# SYNTH32 register map
Vendor: SYNTH-Corp; File version: 1.0
Synthetic device for embedded-toolkit tests
CPU: CM4 r0p1, little endian
Registers are access not given, reset 0x0 unless marked. A register's access mark holds for its fields unless they carry their own. Offsets are from the block's base; lines under a group give offsets from that group; [hi:lo] are bit positions; {n}, {i} and the like mark numbered series; 'fields as' and 'values as' point back to an identical list; <NAME> marks a mode.

## Memory map
0x40004400 USART2 size 0x400
0x40004800 USART3 size 0x400
0x40010400 EXTI — External interrupt/event controller
0x40012C00 TIM1
0x40013800 USART1 size 0x400 — Synthetic USART 1
0x40020000 DMA1
0x40021000 RCC
0x48000000 GPIO{x} (x=A,B,C; step 0x400) — Synthetic GPIO port
0xE000E100 NVIC — 嵌套向量中断控制器（Synthetic）

## Interrupts
11 DMA1_Channel1_IRQn (DMA1) — DMA1 channel 1 interrupt
12 DMA1_Channel2_IRQn (DMA1)
37 USART1_IRQn (USART1) — USART1 global interrupt
39 USART3_IRQn (USART3)

## USART1 — Synthetic USART 1
Base 0x40013800
Same registers: USART2 0x40004400
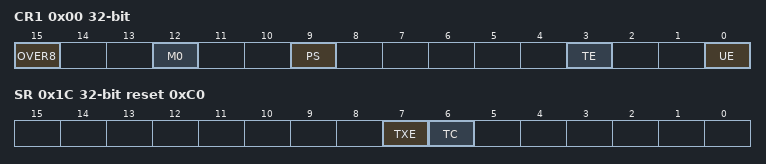
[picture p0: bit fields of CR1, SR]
0x00 CR1 32-bit rw — Control register 1
  [15] OVER8 — Oversampling mode
  [12] M0 — Word length
  [9] PS — Parity selection
    0=EVEN (Even parity); 1=ODD (Odd parity); other=DEFAULT
  [3] TE — Transmitter enable
  [0] UE — USART enable
0x0C BRR — Baud rate register
  [15:0] DIV — Baud rate divisor
0x1C SR ro reset 0xC0 — Status register
  [7] TXE — Transmit data register empty
  [6] TC rw — Transmission complete

## USART3
Base 0x40004800
Registers as USART1; these are added or differ:
0x1C SR reset 0x40
  [7] TXE

## GPIO{x} — Synthetic GPIO port
Base 0x48000000; array of 3, step 0x400
0x00 MODER 32-bit reset 0x1
  [1:0] MODE0 — Port mode bit 0
    0=INPUT; 1=OUTPUT; 2=ALTERNATE; 3=ANALOG
0x14 ODR 16-bit
  [0] OD0

## DMA1
Base 0x40020000
0x00 ISR
  [0] GIF1
0x08 CH{i} (i=1..2; step 0x14) group — DMA channel
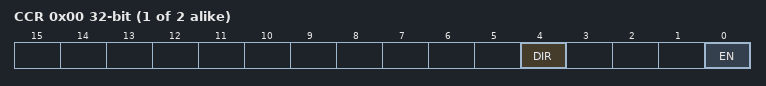
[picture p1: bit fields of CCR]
  0x00 CCR
    [4] DIR, [0] EN
  0x04 CNDTR
    [15:0] NDT

## TIM1
Base 0x40012C00
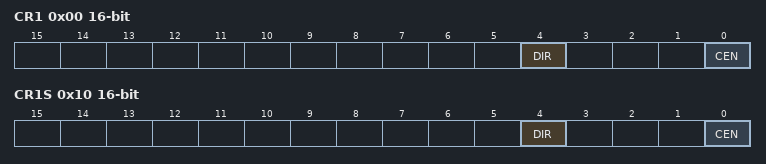
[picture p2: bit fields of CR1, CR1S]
0x00 CR1 16-bit — TIM1 control register 1
  [4] DIR
    0=UP; 1=DOWN
  [0] CEN
0x04 CR2
  [6:4] MMS
    0=RESET; 1=ENABLE; 0b1XX=COMPARE
0x10 CR1S 16-bit — TIM1 control register 1
  [4] DIR
    0=UP; 1=DOWN
  [0] CEN
0x24 CNT ro
  [15:0] CNT
{0x30+4i} CCR{i} (i=1..4)
  [15:0] CCR

## RCC
Base 0x40021000
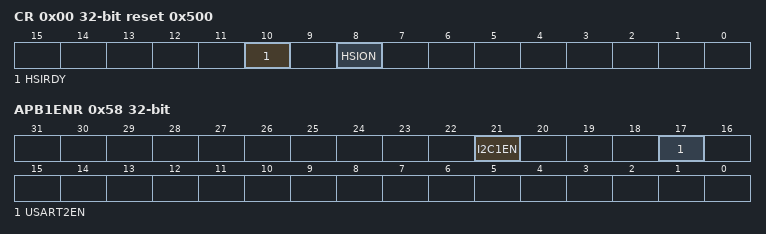
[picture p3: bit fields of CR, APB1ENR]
0x00 CR reset 0x500
  [10] HSIRDY ro, [8] HSION
0x58 APB1ENR
  [21] I2C1EN, [17] USART2EN

## EXTI — External interrupt/event controller
Base 0x40010400
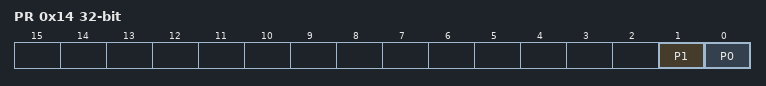
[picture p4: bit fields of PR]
0x14 PR write-1-clears — Pending register
  [1] P1 write-1-sets — Pending bit 1
  [0] P0 read-clears — Pending bit 0

## NVIC — 嵌套向量中断控制器（Synthetic）
Base 0xE000E100
0x00 ISER0 — 中断使能寄存器 0（中断 0-31）
0x04 ISER1 — 中断使能寄存器 1（中断 32-63）
0x280 ICPR0 — 中断清挂起寄存器 0
0x284 ICPR1 — 中断清挂起寄存器 1
0x324 IPR9 — 中断优先级寄存器 9（中断 36-39，每中断 1 字节）
